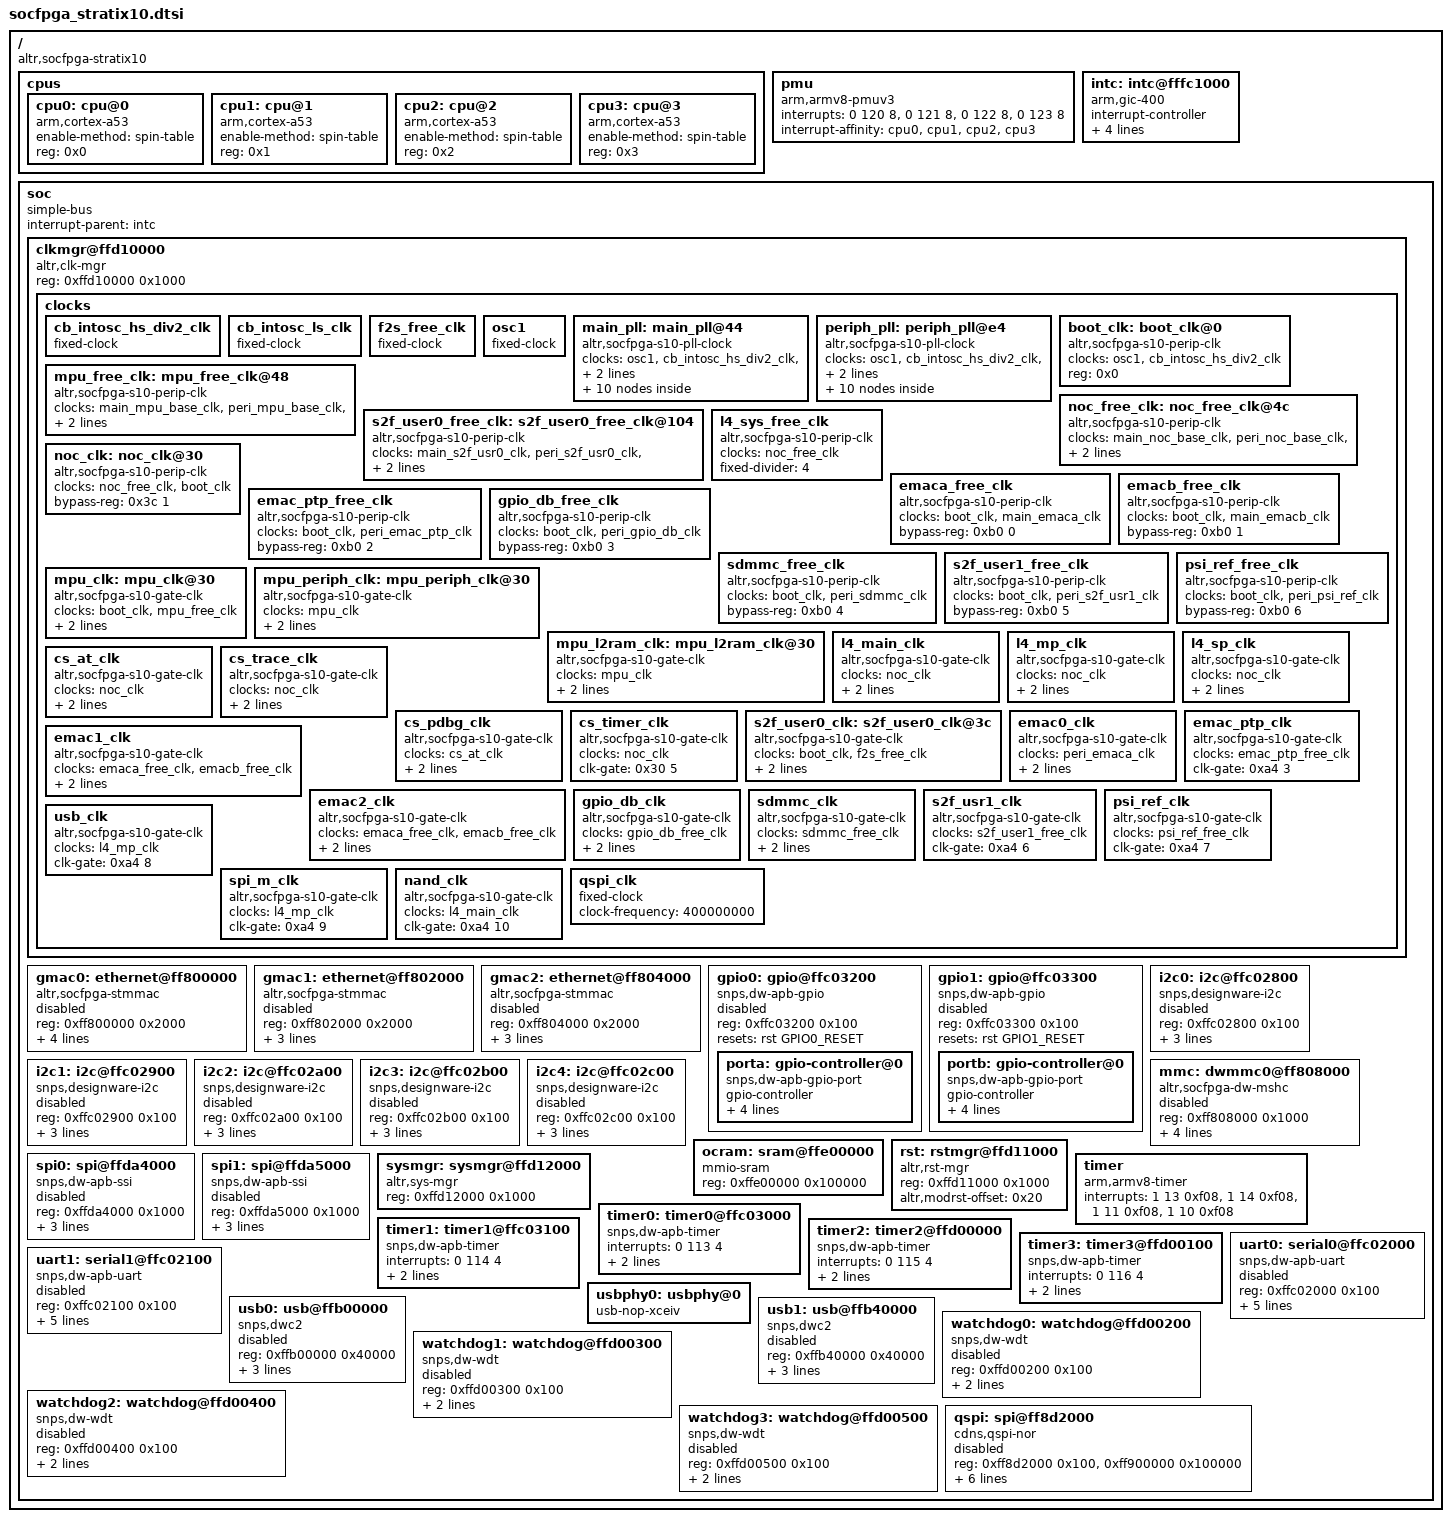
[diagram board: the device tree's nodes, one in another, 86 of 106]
/*
 * Copyright Altera Corporation (C) 2015. All rights reserved.
 *
 * This program is free software; you can redistribute it and/or modify
 * it under the terms and conditions of the GNU General Public License,
 * version 2, as published by the Free Software Foundation.
 *
 * This program is distributed in the hope it will be useful, but WITHOUT
 * ANY WARRANTY; without even the implied warranty of MERCHANTABILITY or
 * FITNESS FOR A PARTICULAR PURPOSE.  See the GNU General Public License for
 * more details.
 *
 * You should have received a copy of the GNU General Public License along with
 * this program.  If not, see <http://www.gnu.org/licenses/>.
 */

/dts-v1/;
#include <dt-bindings/reset/altr,rst-mgr-s10.h>

/ {
	compatible = "altr,socfpga-stratix10";
	#address-cells = <2>;
	#size-cells = <2>;

	cpus {
		#address-cells = <1>;
		#size-cells = <0>;

		cpu0: cpu@0 {
			compatible = "arm,cortex-a53", "arm,armv8";
			device_type = "cpu";
			enable-method = "spin-table";
			reg = <0x0>;
		};

		cpu1: cpu@1 {
			compatible = "arm,cortex-a53", "arm,armv8";
			device_type = "cpu";
			enable-method = "spin-table";
			reg = <0x1>;
		};

		cpu2: cpu@2 {
			compatible = "arm,cortex-a53", "arm,armv8";
			device_type = "cpu";
			enable-method = "spin-table";
			reg = <0x2>;
		};

		cpu3: cpu@3 {
			compatible = "arm,cortex-a53", "arm,armv8";
			device_type = "cpu";
			enable-method = "spin-table";
			reg = <0x3>;
		};
	};

	pmu {
		compatible = "arm,armv8-pmuv3";
		interrupts = <0 120 8>,
			     <0 121 8>,
			     <0 122 8>,
			     <0 123 8>;
		interrupt-affinity = <&cpu0>,
				     <&cpu1>,
				     <&cpu2>,
				     <&cpu3>;
	};

	intc: intc@fffc1000 {
		compatible = "arm,gic-400", "arm,cortex-a15-gic";
		#interrupt-cells = <3>;
		interrupt-controller;
		reg = <0x0 0xfffc1000 0x0 0x1000>,
		      <0x0 0xfffc2000 0x0 0x2000>,
		      <0x0 0xfffc4000 0x0 0x2000>,
		      <0x0 0xfffc6000 0x0 0x2000>;
	};

	soc {
		#address-cells = <1>;
		#size-cells = <1>;
		compatible = "simple-bus";
		device_type = "soc";
		interrupt-parent = <&intc>;
		ranges = <0 0 0 0xffffffff>;

		clkmgr@ffd10000 {
			compatible = "altr,clk-mgr";
			reg = <0xffd10000 0x1000>;

			clocks {
				#address-cells = <1>;
				#size-cells = <0>;

				cb_intosc_hs_div2_clk: cb_intosc_hs_div2_clk {
					#clock-cells = <0>;
					compatible = "fixed-clock";
				};

				cb_intosc_ls_clk: cb_intosc_ls_clk {
					#clock-cells = <0>;
					compatible = "fixed-clock";
				};

				f2s_free_clk: f2s_free_clk {
					#clock-cells = <0>;
					compatible = "fixed-clock";
				};

				osc1: osc1 {
					#clock-cells = <0>;
					compatible = "fixed-clock";
				};

				main_pll: main_pll@44 {
					#address-cells = <1>;
					#size-cells = <0>;
					#clock-cells = <0>;
					compatible = "altr,socfpga-s10-pll-clock";
					clocks = <&osc1>, <&cb_intosc_hs_div2_clk>,
						 <&f2s_free_clk>;
					reg = <0x74>;

					main_mpu_base_clk: main_mpu_base_clk {
						#clock-cells = <0>;
						compatible = "altr,socfpga-s10-perip-clk";
						clocks = <&main_pll>;
						div-reg = <0x84 0 8>;
					};

					main_noc_base_clk: main_noc_base_clk {
						#clock-cells = <0>;
						compatible = "altr,socfpga-s10-perip-clk";
						clocks = <&main_pll>;
						div-reg = <0x88 0 8>;
					};

					main_emaca_clk: main_emaca_clk@68 {
						#clock-cells = <0>;
						compatible = "altr,socfpga-s10-perip-clk";
						clocks = <&main_pll>;
						reg = <0x50>;
					};

					main_emacb_clk: main_emacb_clk@6c {
						#clock-cells = <0>;
						compatible = "altr,socfpga-s10-perip-clk";
						clocks = <&main_pll>;
						reg = <0x54>;
					};

					main_emac_ptp_clk: main_emac_ptp_clk@70 {
						#clock-cells = <0>;
						compatible = "altr,socfpga-s10-perip-clk";
						clocks = <&main_pll>;
						reg = <0x58>;
					};

					main_gpio_db_clk: main_gpio_db_clk@74 {
						#clock-cells = <0>;
						compatible = "altr,socfpga-s10-perip-clk";
						clocks = <&main_pll>;
						reg = <0x5c>;
					};

					main_sdmmc_clk: main_sdmmc_clk@78 {
						#clock-cells = <0>;
						compatible = "altr,socfpga-s10-perip-clk"
;
						clocks = <&main_pll>;
						reg = <0x60>;
					};

					main_s2f_usr0_clk: main_s2f_usr0_clk@7c {
						#clock-cells = <0>;
						compatible = "altr,socfpga-s10-perip-clk";
						clocks = <&main_pll>;
						reg = <0x64>;
					};

					main_s2f_usr1_clk: main_s2f_usr1_clk@80 {
						#clock-cells = <0>;
						compatible = "altr,socfpga-s10-perip-clk";
						clocks = <&main_pll>;
						reg = <0x68>;
					};

					main_psi_ref_clk: main_psi_ref_clk@84 {
						#clock-cells = <0>;
						compatible = "altr,socfpga-s10-perip-clk";
						clocks = <&main_pll>;
						reg = <0x6c>;
					};
				};

				periph_pll: periph_pll@e4 {
					#address-cells = <1>;
					#size-cells = <0>;
					#clock-cells = <0>;
					compatible = "altr,socfpga-s10-pll-clock";
					clocks = <&osc1>, <&cb_intosc_hs_div2_clk>,
						 <&f2s_free_clk>;
					reg = <0xe4>;

					peri_mpu_base_clk: peri_mpu_base_clk {
						#clock-cells = <0>;
						compatible = "altr,socfpga-s10-perip-clk";
						clocks = <&periph_pll>;
						reg = <0xf4 0 8>;
					};

					peri_noc_base_clk: peri_noc_base_clk {
						#clock-cells = <0>;
						compatible = "altr,socfpga-s10-perip-clk";
						clocks = <&periph_pll>;
						reg = <0xf8 0 8>;
					};

					peri_emaca_clk: peri_emaca_clk@e8 {
						#clock-cells = <0>;
						compatible = "altr,socfpga-s10-perip-clk";
						clocks = <&main_pll>, <&periph_pll>,
							 <&osc1>, <&cb_intosc_hs_div2_clk>,							    <&f2s_free_clk>;
						reg = <0xbc>;
					};

					peri_emacb_clk: peri_emacb_clk@ec {
						#clock-cells = <0>;
						compatible = "altr,socfpga-s10-perip-clk";
						clocks = <&main_pll>, <&periph_pll>,
							 <&osc1>, <&cb_intosc_hs_div2_clk>,							    <&f2s_free_clk>;
						reg = <0xc0>;
					};

					peri_emac_ptp_clk: peri_emac_ptp_clk@f0 {
						#clock-cells = <0>;
						compatible = "altr,socfpga-s10-perip-clk";
						clocks = <&main_pll>, <&periph_pll>,
							 <&osc1>, <&cb_intosc_hs_div2_clk>,							    <&f2s_free_clk>;
						reg = <0xc4>;
					};

					peri_gpio_db_clk: peri_gpio_db_clk@f4 {
						#clock-cells = <0>;
						compatible = "altr,socfpga-s10-perip-clk";
						clocks = <&main_pll>, <&periph_pll>,
							 <&osc1>, <&cb_intosc_hs_div2_clk>,							    <&f2s_free_clk>;
						reg = <0xc8>;
					};

					peri_sdmmc_clk: peri_sdmmc_clk@f8 {
						#clock-cells = <0>;
						compatible = "altr,socfpga-s10-perip-clk";
						clocks = <&main_pll>, <&periph_pll>,
							 <&osc1>, <&cb_intosc_hs_div2_clk>,							    <&f2s_free_clk>;
						reg = <0xcc>;
					};

					peri_s2f_usr0_clk: peri_s2f_usr0_clk@fc {
						#clock-cells = <0>;
						compatible = "altr,socfpga-s10-perip-clk";
						clocks = <&periph_pll>;
						reg = <0xd0>;
					};

					peri_s2f_usr1_clk: peri_s2f_usr1_clk@100 {
						#clock-cells = <0>;
						compatible = "altr,socfpga-s10-perip-clk";
						clocks = <&main_pll>, <&periph_pll>,
							 <&osc1>, <&cb_intosc_hs_div2_clk>,							    <&f2s_free_clk>;
						reg = <0xd4>;
					};

					peri_psi_ref_clk: peri_psi_ref_clk@104 {
						#clock-cells = <0>;
						compatible = "altr,socfpga-s10-perip-clk";
						clocks = <&main_pll>, <&periph_pll>,
							 <&osc1>, <&cb_intosc_hs_div2_clk>,							    <&f2s_free_clk>;
						reg = <0xd8>;
					};
				};

				boot_clk: boot_clk@0 {
					#clock-cells = <0>;
					compatible = "altr,socfpga-s10-perip-clk";
					clocks = <&osc1>, <&cb_intosc_hs_div2_clk>;
					reg = <0x0>;
				};

				mpu_free_clk: mpu_free_clk@48 {
					#clock-cells = <0>;
					compatible = "altr,socfpga-s10-perip-clk";
					clocks = <&main_mpu_base_clk>, <&peri_mpu_base_clk>,
						 <&osc1>, <&cb_intosc_hs_div2_clk>,
						 <&f2s_free_clk>;
					reg = <0x48>;
				};

				noc_free_clk: noc_free_clk@4c {
					#clock-cells = <0>;
					compatible = "altr,socfpga-s10-perip-clk";
					clocks = <&main_noc_base_clk>, <&peri_noc_base_clk>,
						 <&osc1>, <&cb_intosc_hs_div2_clk>,
						 <&f2s_free_clk>;
					reg = <0x4c>;
				};

				s2f_user0_free_clk: s2f_user0_free_clk@104 {
					#clock-cells = <0>;
					compatible = "altr,socfpga-s10-perip-clk";
					clocks = <&main_s2f_usr0_clk>, <&peri_s2f_usr0_clk>,
						 <&osc1>, <&cb_intosc_hs_div2_clk>,
						 <&f2s_free_clk>;
					reg = <0x64>;
				};

				l4_sys_free_clk: l4_sys_free_clk {
					#clock-cells = <0>;
					compatible = "altr,socfpga-s10-perip-clk";
					clocks = <&noc_free_clk>;
					fixed-divider = <4>;
				};

				noc_clk: noc_clk@30 {
					#clock-cells = <0>;
					compatible = "altr,socfpga-s10-perip-clk";
					clocks = <&noc_free_clk>, <&boot_clk>;
					bypass-reg = <0x3c 1>;
				};

				emaca_free_clk: emaca_free_clk {
					#clock-cells = <0>;
					compatible = "altr,socfpga-s10-perip-clk";
					clocks = <&boot_clk>, <&main_emaca_clk>;
					bypass-reg = <0xb0 0>;
				};

				emacb_free_clk: emacb_free_clk {
					#clock-cells = <0>;
					compatible = "altr,socfpga-s10-perip-clk";
					clocks = <&boot_clk>, <&main_emacb_clk>;
					bypass-reg = <0xb0 1>;
				};

				emac_ptp_free_clk: emac_ptp_free_clk {
					#clock-cells = <0>;
					compatible = "altr,socfpga-s10-perip-clk";
					clocks = <&boot_clk>, <&peri_emac_ptp_clk>;
					bypass-reg = <0xb0 2>;
				};

				gpio_db_free_clk: gpio_db_free_clk {
					#clock-cells = <0>;
					compatible = "altr,socfpga-s10-perip-clk";
					clocks = <&boot_clk>, <&peri_gpio_db_clk>;
					bypass-reg = <0xb0 3>;
				};

				sdmmc_free_clk: sdmmc_free_clk {
					#clock-cells = <0>;
					compatible = "altr,socfpga-s10-perip-clk";
					clocks = <&boot_clk>, <&peri_sdmmc_clk>;
					bypass-reg = <0xb0 4>;
				};

				s2f_user1_free_clk: s2f_user1_free_clk {
					#clock-cells = <0>;
					compatible = "altr,socfpga-s10-perip-clk";
					clocks = <&boot_clk>, <&peri_s2f_usr1_clk>;
					bypass-reg = <0xb0 5>;
				};

				psi_ref_free_clk: psi_ref_free_clk {
					#clock-cells = <0>;
					compatible = "altr,socfpga-s10-perip-clk";
					clocks = <&boot_clk>, <&peri_psi_ref_clk>;
					bypass-reg = <0xb0 6>;
				};

				mpu_clk: mpu_clk@30 {
					#clock-cells = <0>;
					compatible = "altr,socfpga-s10-gate-clk";
					clocks = <&boot_clk>, <&mpu_free_clk>;
					bypass-reg = <0x3c 0>;
					clk-gate = <0x30 0>;
				};

				mpu_periph_clk: mpu_periph_clk@30 {
					#clock-cells = <0>;
					compatible = "altr,socfpga-s10-gate-clk";
					clocks = <&mpu_clk>;
					fixed-divider = <4>;
					clk-gate = <0x30 0>;
				};

				mpu_l2ram_clk: mpu_l2ram_clk@30 {
					#clock-cells = <0>;
					compatible = "altr,socfpga-s10-gate-clk";
					clocks = <&mpu_clk>;
					fixed-divider = <2>;
					clk-gate = <0x30 0>;
				};

				l4_main_clk: l4_main_clk {
					#clock-cells = <0>;
					compatible = "altr,socfpga-s10-gate-clk";
					clocks = <&noc_clk>;
					div-reg = <0x70 0 2>;
					clk-gate = <0x30 1>;
				};

				l4_mp_clk: l4_mp_clk {
					#clock-cells = <0>;
					compatible = "altr,socfpga-s10-gate-clk";
					clocks = <&noc_clk>;
					div-reg= <0x70 8 2>;
					clk-gate = <0x30 2>;
				};

				l4_sp_clk: l4_sp_clk {
					#clock-cells = <0>;
					compatible = "altr,socfpga-s10-gate-clk";
					clocks = <&noc_clk>;
					div-reg= <0x70 16 2>;
					clk-gate = <0x30 3>;
				};

				cs_at_clk: cs_at_clk {
					#clock-cells = <0>;
					compatible = "altr,socfpga-s10-gate-clk";
					clocks = <&noc_clk>;
					div-reg= <0x70 24 2>;
					clk-gate = <0x30 4>;
				};

				cs_trace_clk: cs_trace_clk {
					#clock-cells = <0>;
					compatible = "altr,socfpga-s10-gate-clk";
					clocks = <&noc_clk>;
					div-reg= <0x70 26 2>;
					clk-gate = <0x30 4>;
				};

				cs_pdbg_clk: cs_pdbg_clk {
					#clock-cells = <0>;
					compatible = "altr,socfpga-s10-gate-clk";
					clocks = <&cs_at_clk>;
					div-reg= <0x70 28 1>;
					clk-gate = <0x30 4>;
				};

				cs_timer_clk: cs_timer_clk {
					#clock-cells = <0>;
					compatible = "altr,socfpga-s10-gate-clk";
					clocks = <&noc_clk>;
					clk-gate = <0x30 5>;
				};

				s2f_user0_clk: s2f_user0_clk@3c {
					#clock-cells = <0>;
					compatible = "altr,socfpga-s10-gate-clk";
					clocks = <&boot_clk>, <&f2s_free_clk>;
					bypass-reg = <0x3c 2>;
					clk-gate = <0x30 6>;
				};

				emac0_clk: emac0_clk {
					#clock-cells = <0>;
					compatible = "altr,socfpga-s10-gate-clk";
					clocks = <&peri_emaca_clk>;
					fixed-divider = <4>;
					clk-gate = <0xa4 0>;
				};

				emac1_clk: emac1_clk {
					#clock-cells = <0>;
					compatible = "altr,socfpga-s10-gate-clk";
					clocks = <&emaca_free_clk>, <&emacb_free_clk>;
					bypass-reg = <0xdc 27>;
					clk-gate = <0xa4 1>;
				};

				emac2_clk: emac2_clk {
					#clock-cells = <0>;
					compatible = "altr,socfpga-s10-gate-clk";
					clocks = <&emaca_free_clk>, <&emacb_free_clk>;
					bypass-reg = <0xdc 28>;
					clk-gate = <0xa4 2>;
				};

				emac_ptp_clk: emac_ptp_clk {
					#clock-cells = <0>;
					compatible = "altr,socfpga-s10-gate-clk";
					clocks = <&emac_ptp_free_clk>;
					clk-gate = <0xa4 3>;
				};

				gpio_db_clk: gpio_db_clk {
					#clock-cells = <0>;
					compatible = "altr,socfpga-s10-gate-clk";
					clocks = <&gpio_db_free_clk>;
					div-reg = <0xe0>;
					clk-gate = <0xa4 4>;
				};

				sdmmc_clk: sdmmc_clk {
					#clock-cells = <0>;
					compatible = "altr,socfpga-s10-gate-clk";
					clocks = <&sdmmc_free_clk>;
					fixed-divider = <4>;
					clk-gate = <0xa4 5>;
				};

				s2f_usr1_clk: s2f_usr1_clk {
					#clock-cells = <0>;
					compatible = "altr,socfpga-s10-gate-clk";
					clocks = <&s2f_user1_free_clk>;
					clk-gate = <0xa4 6>;
				};

				psi_ref_clk: psi_ref_clk {
					#clock-cells = <0>;
					compatible = "altr,socfpga-s10-gate-clk";
					clocks = <&psi_ref_free_clk>;
					clk-gate = <0xa4 7>;
				};

				usb_clk: usb_clk {
					#clock-cells = <0>;
					compatible = "altr,socfpga-s10-gate-clk";
					clocks = <&l4_mp_clk>;
					clk-gate = <0xa4 8>;
				};

				spi_m_clk: spi_m_clk {
					#clock-cells = <0>;
					compatible = "altr,socfpga-s10-gate-clk";
					clocks = <&l4_mp_clk>;
					clk-gate = <0xa4 9>;
				};

				nand_clk: nand_clk {
					#clock-cells = <0>;
					compatible = "altr,socfpga-s10-gate-clk";
					clocks = <&l4_main_clk>;
					clk-gate = <0xa4 10>;
				};

				qspi_clk: qspi_clk {
					#clock-cells = <0>;
					compatible = "fixed-clock";
					clock-frequency = <400000000>;
				};
			};
		};

		gmac0: ethernet@ff800000 {
			compatible = "altr,socfpga-stmmac", "snps,dwmac-3.74a", "snps,dwmac";
			reg = <0xff800000 0x2000>;
			interrupts = <0 90 4>;
			interrupt-names = "macirq";
			mac-address = [00 00 00 00 00 00];
			clocks = <&emac0_clk>;
			clock-names = "stmmaceth";
			resets = <&rst EMAC0_RESET>;
			reset-names = "stmmaceth";
			status = "disabled";
		};

		gmac1: ethernet@ff802000 {
			compatible = "altr,socfpga-stmmac", "snps,dwmac-3.74a", "snps,dwmac";
			reg = <0xff802000 0x2000>;
			interrupts = <0 91 4>;
			interrupt-names = "macirq";
			mac-address = [00 00 00 00 00 00];
			resets = <&rst EMAC1_RESET>;
			reset-names = "stmmaceth";
			status = "disabled";
		};

		gmac2: ethernet@ff804000 {
			compatible = "altr,socfpga-stmmac", "snps,dwmac-3.74a", "snps,dwmac";
			reg = <0xff804000 0x2000>;
			interrupts = <0 92 4>;
			interrupt-names = "macirq";
			mac-address = [00 00 00 00 00 00];
			resets = <&rst EMAC2_RESET>;
			reset-names = "stmmaceth";
			status = "disabled";
		};

		gpio0: gpio@ffc03200 {
			#address-cells = <1>;
			#size-cells = <0>;
			compatible = "snps,dw-apb-gpio";
			reg = <0xffc03200 0x100>;
			resets = <&rst GPIO0_RESET>;
			status = "disabled";

			porta: gpio-controller@0 {
				compatible = "snps,dw-apb-gpio-port";
				gpio-controller;
				#gpio-cells = <2>;
				snps,nr-gpios = <24>;
				reg = <0>;
				interrupt-controller;
				#interrupt-cells = <2>;
				interrupts = <0 110 4>;
			};
		};

		gpio1: gpio@ffc03300 {
			#address-cells = <1>;
			#size-cells = <0>;
			compatible = "snps,dw-apb-gpio";
			reg = <0xffc03300 0x100>;
			resets = <&rst GPIO1_RESET>;
			status = "disabled";

			portb: gpio-controller@0 {
				compatible = "snps,dw-apb-gpio-port";
				gpio-controller;
				#gpio-cells = <2>;
				snps,nr-gpios = <24>;
				reg = <0>;
				interrupt-controller;
				#interrupt-cells = <2>;
				interrupts = <0 110 4>;
			};
		};

		i2c0: i2c@ffc02800 {
			#address-cells = <1>;
			#size-cells = <0>;
			compatible = "snps,designware-i2c";
			reg = <0xffc02800 0x100>;
			interrupts = <0 103 4>;
			clocks = <&l4_sp_clk>;
			resets = <&rst I2C0_RESET>;
			status = "disabled";
		};

		i2c1: i2c@ffc02900 {
			#address-cells = <1>;
			#size-cells = <0>;
			compatible = "snps,designware-i2c";
			reg = <0xffc02900 0x100>;
			interrupts = <0 104 4>;
			clocks = <&l4_sp_clk>;
			resets = <&rst I2C1_RESET>;
			status = "disabled";
		};

		i2c2: i2c@ffc02a00 {
			#address-cells = <1>;
			#size-cells = <0>;
			compatible = "snps,designware-i2c";
			reg = <0xffc02a00 0x100>;
			interrupts = <0 105 4>;
			clocks = <&l4_sp_clk>;
			resets = <&rst I2C2_RESET>;
			status = "disabled";
		};

		i2c3: i2c@ffc02b00 {
			#address-cells = <1>;
			#size-cells = <0>;
			compatible = "snps,designware-i2c";
			reg = <0xffc02b00 0x100>;
			interrupts = <0 106 4>;
			clocks = <&l4_sp_clk>;
			resets = <&rst I2C3_RESET>;
			status = "disabled";
		};

		i2c4: i2c@ffc02c00 {
			#address-cells = <1>;
			#size-cells = <0>;
			compatible = "snps,designware-i2c";
			reg = <0xffc02c00 0x100>;
			interrupts = <0 107 4>;
			clocks = <&l4_sp_clk>;
			resets = <&rst I2C4_RESET>;
			status = "disabled";
		};

		mmc: dwmmc0@ff808000 {
			#address-cells = <1>;
			#size-cells = <0>;
			compatible = "altr,socfpga-dw-mshc";
			reg = <0xff808000 0x1000>;
			interrupts = <0 96 4>;
			fifo-depth = <0x400>;
			clocks = <&l4_mp_clk>, <&sdmmc_clk>;
			clock-names = "biu", "ciu";
			resets = <&rst SDMMC_RESET>;
			reset-names = "reset";
			status = "disabled";
		};

		ocram: sram@ffe00000 {
			compatible = "mmio-sram";
			reg = <0xffe00000 0x100000>;
		};

		rst: rstmgr@ffd11000 {
			#reset-cells = <1>;
			compatible = "altr,rst-mgr";
			reg = <0xffd11000 0x1000>;
			altr,modrst-offset = <0x20>;
		};

		spi0: spi@ffda4000 {
			compatible = "snps,dw-apb-ssi";
			#address-cells = <1>;
			#size-cells = <0>;
			reg = <0xffda4000 0x1000>;
			interrupts = <0 101 4>;
			num-chipselect = <4>;
			bus-num = <0>;
			status = "disabled";
		};

		spi1: spi@ffda5000 {
			compatible = "snps,dw-apb-ssi";
			#address-cells = <1>;
			#size-cells = <0>;
			reg = <0xffda5000 0x1000>;
			interrupts = <0 102 4>;
			num-chipselect = <4>;
			bus-num = <0>;
			status = "disabled";
		};

		sysmgr: sysmgr@ffd12000 {
			compatible = "altr,sys-mgr", "syscon";
			reg = <0xffd12000 0x1000>;
		};

		/* Local timer */
		timer {
			compatible = "arm,armv8-timer";
			interrupts = <1 13 0xf08>,
				     <1 14 0xf08>,
				     <1 11 0xf08>,
				     <1 10 0xf08>;
		};

		timer0: timer0@ffc03000 {
			compatible = "snps,dw-apb-timer";
			interrupts = <0 113 4>;
			reg = <0xffc03000 0x100>;
			clocks = <&l4_sp_clk>;
			clock-names = "timer";
		};

		timer1: timer1@ffc03100 {
			compatible = "snps,dw-apb-timer";
			interrupts = <0 114 4>;
			reg = <0xffc03100 0x100>;
			clocks = <&l4_sp_clk>;
			clock-names = "timer";
		};

		timer2: timer2@ffd00000 {
			compatible = "snps,dw-apb-timer";
			interrupts = <0 115 4>;
			reg = <0xffd00000 0x100>;
			clocks = <&l4_sys_free_clk>;
			clock-names = "timer";
		};

		timer3: timer3@ffd00100 {
			compatible = "snps,dw-apb-timer";
			interrupts = <0 116 4>;
			reg = <0xffd00100 0x100>;
			clocks = <&l4_sys_free_clk>;
			clock-names = "timer";
		};

		uart0: serial0@ffc02000 {
			compatible = "snps,dw-apb-uart";
			reg = <0xffc02000 0x100>;
			interrupts = <0 108 4>;
			reg-shift = <2>;
			reg-io-width = <4>;
			clocks = <&l4_sp_clk>;
			resets = <&rst UART0_RESET>;
			status = "disabled";
		};

		uart1: serial1@ffc02100 {
			compatible = "snps,dw-apb-uart";
			reg = <0xffc02100 0x100>;
			interrupts = <0 109 4>;
			reg-shift = <2>;
			reg-io-width = <4>;
			clocks = <&l4_sp_clk>;
			resets = <&rst UART1_RESET>;
			status = "disabled";
		};

		usbphy0: usbphy@0 {
			#phy-cells = <0>;
			compatible = "usb-nop-xceiv";
			status = "okay";
		};

		usb0: usb@ffb00000 {
			compatible = "snps,dwc2";
			reg = <0xffb00000 0x40000>;
			interrupts = <0 93 4>;
			phys = <&usbphy0>;
			phy-names = "usb2-phy";
			resets = <&rst USB0_RESET>;
			reset-names = "dwc2";
			status = "disabled";
		};

		usb1: usb@ffb40000 {
			compatible = "snps,dwc2";
			reg = <0xffb40000 0x40000>;
			interrupts = <0 94 4>;
			phys = <&usbphy0>;
			phy-names = "usb2-phy";
			resets = <&rst USB1_RESET>;
			reset-names = "dwc2";
			status = "disabled";
		};

		watchdog0: watchdog@ffd00200 {
			compatible = "snps,dw-wdt";
			reg = <0xffd00200 0x100>;
			interrupts = <0 117 4>;
			resets = <&rst WATCHDOG0_RESET>;
			status = "disabled";
		};

		watchdog1: watchdog@ffd00300 {
			compatible = "snps,dw-wdt";
			reg = <0xffd00300 0x100>;
			interrupts = <0 118 4>;
			resets = <&rst WATCHDOG1_RESET>;
			status = "disabled";
		};

		watchdog2: watchdog@ffd00400 {
			compatible = "snps,dw-wdt";
			reg = <0xffd00400 0x100>;
			interrupts = <0 125 4>;
			resets = <&rst WATCHDOG2_RESET>;
			status = "disabled";
		};

		watchdog3: watchdog@ffd00500 {
			compatible = "snps,dw-wdt";
			reg = <0xffd00500 0x100>;
			interrupts = <0 126 4>;
			resets = <&rst WATCHDOG3_RESET>;
			status = "disabled";
		};

		qspi: spi@ff8d2000 {
			compatible = "cdns,qspi-nor";
			#address-cells = <1>;
			#size-cells = <0>;
			reg = <0xff8d2000 0x100>,
			      <0xff900000 0x100000>;
			interrupts = <0 3 4>;
			cdns,fifo-depth = <128>;
			cdns,fifo-width = <4>;
			cdns,trigger-address = <0x00000000>;
			clocks = <&qspi_clk>;
			bus-num = <1>;

			status = "disabled";
		};
	};
};
